# CM85F register map
Registers are read-write, no defined reset value unless marked. A register's access mark holds for its fields unless they carry their own. Offsets are from the block's base; [hi:lo] are bit positions; {n}, {i} and the like mark numbered series; 'fields as' and 'values as' point back to an identical list.

## SCB — System Control Block
Base 0xE000ECFC
0x00 REVIDR ro — Revision ID Register provides additional implementation-specific minor revision that can be interpreted with the CPUID register
  [31:0] IMPLEMENTATION_SPECIFIC — Implementation-specific minor revision information that can be interpreted with the CPUID register.
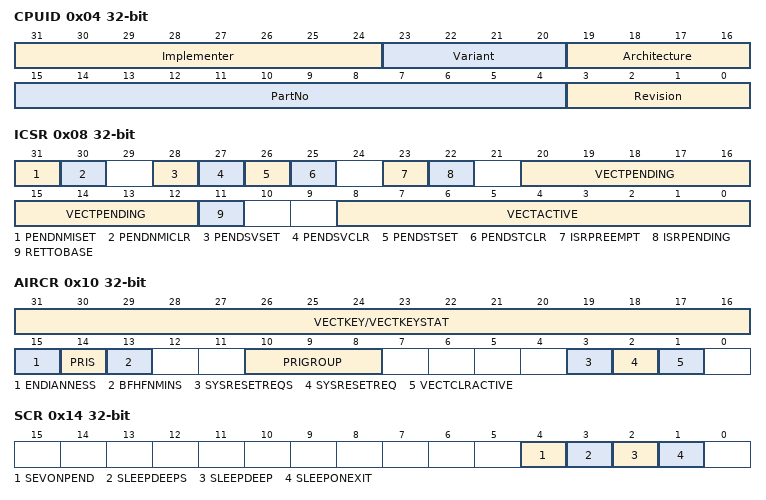
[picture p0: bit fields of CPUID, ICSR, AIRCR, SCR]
0x04 CPUID ro — CPUID Base Register contains the processor part number, version, and implementation information
  [31:24] Implementer — Implementer code
  [23:20] Variant — Variant number, the n value in the rnpm product revision identifier
  [19:16] Architecture — Reads as 0xF
    15=Armv8.1-M with Main Extension
  [15:4] PartNo — Part number of the processor
  [3:0] Revision — Revision number, the m value in the rnpm product revision identifier
0x08 ICSR — Interrupt Control and State Register provides a set-pending bit for the non-maskable interrupt exception, and set-pending and clear-pending bits for the PendSV and SysTick exceptions
  [31] PENDNMISET — On writes, makes the NMI exception pending
    0=On writes, ignored; on reads, NMI exception is not pending; 1=On writes, Changes NMI exception state to pending; on reads, NMI exception is pending
  [30] PENDNMICLR — Pend NMI clear bit (write-only)
    0=No effect; 1=Clear pending status
  [28] PENDSVSET — PendSV set-pending bit
    0=On writes, ignored; on reads, PendSV exception is not pending; 1=On writes, Changes PendSV exception state to pending; on reads, PendSV exception is pending
  [27] PENDSVCLR — PendSV clear-pending bit (write-only)
    0=No effect; 1=Clear pending status
  [26] PENDSTSET — SysTick exception set-pending bit
    0=On writes, ignored; on reads, SysTick exception is not pending; 1=On writes, Changes SysTick exception state to pending; on reads, SysTick exception is pending
  [25] PENDSTCLR — SysTick exception clear-pending bit
    0=No effect; 1=Clear pending status
  [23] ISRPREEMPT — Indicates whether a pending exception is handled on exit from debug state.
    0=Pending exception is not handled on exit from debug state; 1=Pending exception is handled on exit from debug state
  [22] ISRPENDING — Interrupt pending flag, excluding NMI and Faults
    0=Interrupt not pending; 1=Interrupt pending
  [20:12] VECTPENDING — Indicates the exception number of the highest priority pending enabled exception
  [11] RETTOBASE — Indicates whether there are pre-empted active exceptions
    0=There are pre-empted active exceptions to execute; 1=There are no active exceptions, or the currently executing exception is the only active exception
  [8:0] VECTACTIVE — Contains the active exception number
0x0C VTOR — Vector Table Offset Register indicates the offset of the vector table base address from memory address 0x00000000
  [31:7] TBLOFF — Bits[31:7] of the vector table address
0x10 AIRCR — Application Interrupt and Reset Control Register sets or returns interrupt control data
  [31:16] VECTKEY/VECTKEYSTAT — Register key. Reads as 0x0FA05, On writes, write 0x5FA to VECTKEY, otherwise the write is ignored.
  [15] ENDIANNESS — Data endianness
    0=Little endian; 1=Big endian
  [14] PRIS — Prioritize Secure exceptions
    0=Priority ranges of Secure and Non-secure exceptions are identical; 1=Non-secure exceptions are de-prioritized
  [13] BFHFNMINS — BusFault, HardFault, and NMI Non-secure enable
    0=BusFault, HardFault, and NMI are Secure; 1=BusFault and NMI are Non-secure and exceptions can target Non-secure HardFault
  [10:8] PRIGROUP — Interrupt priority grouping
  [3] SYSRESETREQS — System reset request, Secure state only
    0=SYSRESETREQ functionality is available to both Security states; 1=SYSRESETREQ functionality is only available to Secure state
  [2] SYSRESETREQ — System Reset Request
    0=Do not request a reset; 1=Request reset
  [1] VECTCLRACTIVE — Reserved for Debug use. This bit reads as 0. When writing to the register you must write 0 to this bit, otherwise behavior is UNPREDICTABLE
0x14 SCR ro — System Control Register controls features of entry to and exit from low-power state
  [4] SEVONPEND — Determines whether an interrupt assigned to the same Security state as the SEVONPEND bit transitioning from inactive state to pending state generates a wakeup event
    0=Transitions from inactive to pending are not wakeup events; 1=Transitions from inactive to pending are wakeup events
  [3] SLEEPDEEPS — Controls whether the SLEEPDEEP bit is only accessible from the Secure state
    0=The SLEEPDEEP bit accessible from both Security states; 1=The SLEEPDEEP bit behaves as RAZ/WI when accessed from the Non-secure state
  [2] SLEEPDEEP — Indicates whether the processor uses sleep or deep sleep as its low-power mode
    0=Sleep; 1=Deep sleep
  [1] SLEEPONEXIT — Indicates sleep-on-exit when returning from Handler mode to Thread mode
    0=Do not sleep when returning to Thread mode; 1=Enter sleep, or deep sleep, on return from an ISR
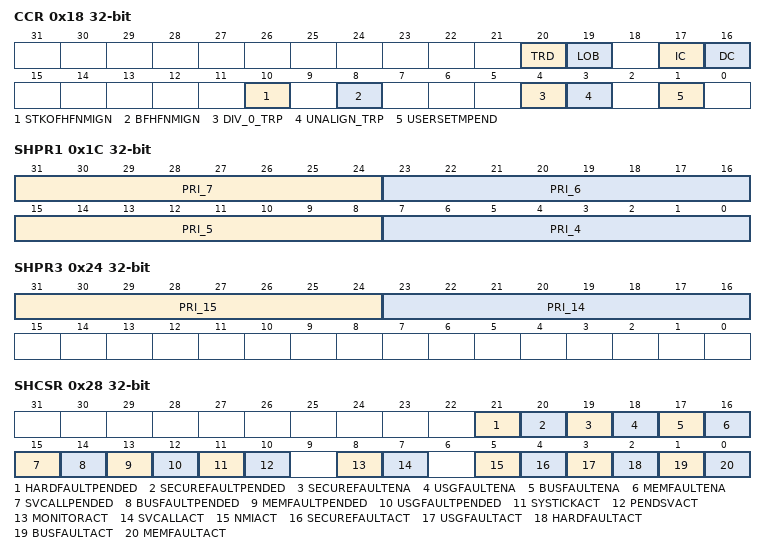
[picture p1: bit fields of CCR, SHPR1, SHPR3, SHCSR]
0x18 CCR — Configuration and Control Register indicates some aspects of the behavior of the processor
  [20] TRD — Thread reentrancy disabled
    0=Integrity signature checking not performed; 1=Integrity signature checking performed
  [19] LOB — Loop and branch info cache enable
    0=Branch cache disabled for the selected Security state; 1=Branch cache enabled for the selected Security state
  [17] IC — Instruction cache enable
    0=Instruction caches disabled for the selected Security state; 1=Instruction caches enabled for the selected Security state
  [16] DC — Data cache enable
    0=Data caching disabled; 1=Data caching enabled
  [10] STKOFHFNMIGN — Controls the effect of a stack limit violation while executing at a requested priority less than 0
    0=Stack limit faults not ignored; 1=Stack limit faults at requested priorities of less than 0 ignored
  [8] BFHFNMIGN — Determines the effect of precise bus faults on handlers running at a requested priority less than 0
    0=Precise bus faults are not ignored; 1=Precise bus faults at requested priorities of less than 0 are ignored
  [4] DIV_0_TRP — Divide by zero trap. Controls the generation of a DIVBYZERO UsageFault when attempting to perform integer division by zero.
    0=Trapping disabled; 1=Trapping enabled
  [3] UNALIGN_TRP — Controls the trapping of unaligned word or halfword accesses
    0=Trapping disabled; 1=Trapping enabled
  [1] USERSETMPEND — User set main pending. Determines whether unprivileged accesses are permitted to pend interrupts from the STIR.
    0=Unprivileged accesses to the STIR generate a fault; 1=Unprivileged accesses to the STIR are permitted
0x1C SHPR1 — System Handler Priority Register 1 sets or returns priority for system handlers 4-7
  [31:24] PRI_7 — Priority of system handler 7, SecureFault
  [23:16] PRI_6 — Priority of system handler 6, UsageFault
  [15:8] PRI_5 — Priority of system handler 5, BusFault
  [7:0] PRI_4 — Priority of system handler 4, MemManage
0x20 SHPR2 — System Handler Priority Register 2 sets or returns priority for system handler 8-11
  [31:24] PRI_11 — Priority of system handler 11, SVCall
0x24 SHPR3 — System Handler Priority Register 3 sets or returns priority for system handlers 12-15
  [31:24] PRI_15 — Priority of system handler 15, SysTick
  [23:16] PRI_14 — Priority of system handler 14, PendSV
0x28 SHCSR — System Handler Control and State Register enables the system handlers and indicates the pending status of the BusFault, MemManage fault, and SVC exceptions, and indicates the active status of the system handlers
  [21] HARDFAULTPENDED — HardFault exception pended state bit, set to 1 to allow exception modification
  [20] SECUREFAULTPENDED — SecureFault exception pended state bit, set to 1 to allow exception modification
  [19] SECUREFAULTENA — RES0
  [18] USGFAULTENA — UsageFault enable
    0=Disable the exception; 1=Enable the exception
  [17] BUSFAULTENA — BusFault enable
    0=Disable the exception; 1=Enable the exception
  [16] MEMFAULTENA — MemManage enable
    0=Disable the exception; 1=Enable the exception
  [15] SVCALLPENDED — SVCall pending
    0=SVCall execption is not pending; 1=SVCall execption is pending
  [14] BUSFAULTPENDED — BusFault pending
    values as SVCALLPENDED
  [13] MEMFAULTPENDED — MemManage exception pending
    values as SVCALLPENDED
  [12] USGFAULTPENDED — UsageFault exception pending
    values as SVCALLPENDED
  [11] SYSTICKACT — SysTick exception active
    0=SVCall execption is not active; 1=SVCall execption is active
  [10] PENDSVACT — PendSV exception active
    0=PendSV exception is not active; 1=PendSV exception is active
  [8] MONITORACT — Debug monitor active
    0=DebugMonitor not active; 1=DebugMonitor is active
  [7] SVCALLACT — SVCall active
    0=SVCall is not active; 1=SVCall is active
  [5] NMIACT — NMI exception active
    0=NMI exception is not active; 1=NMI exception is active
  [4] SECUREFAULTACT — SecureFault exception active state
    0=SecureFault exception is not active; 1=SecureFault exception is active
  [3] USGFAULTACT — UsageFault exception active
    0=UsageFault exception is not active; 1=UsageFault exception is active
  [2] HARDFAULTACT — HardFault exception active
    0=HardFault exception is not active; 1=HardFault exception is active
  [1] BUSFAULTACT — BusFault exception active
    0=BusFault exception is not active; 1=BusFault exception is active
  [0] MEMFAULTACT — MemManage exception active
    0=MemManage exception is not active; 1=MemManage exception is active
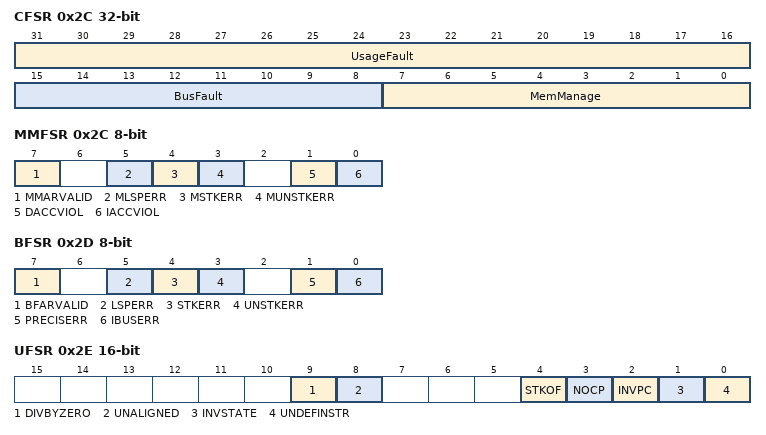
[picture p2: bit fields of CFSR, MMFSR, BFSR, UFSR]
0x2C CFSR — Configurable Fault Status Register indicates the cause of a MemManage fault, BusFault, or UsageFault
  [31:16] UsageFault — Provides information on UsageFault exceptions
  [15:8] BusFault — Provides information on BusFault exceptions
  [7:0] MemManage — Provides information on MemManage exceptions
0x2C MMFSR 8-bit — MemManage Fault Status Register indicates the cause of memory access faults
  [7] MMARVALID — MemManage Fault Address Register (MMFAR) valid flag
    0=MMFAR content not valid; 1=MMFAR content valid
  [5] MLSPERR — MemManage lazy state preservation error flag
    0=No MemManage fault occurred during floating-point lazy state preservation; 1=A MemManage fault occurred during floating-point lazy state preservation
  [4] MSTKERR — MemManage fault on stacking for exception entry
    0=No stacking fault; 1=Stacking for an exception entry has caused one or more access violations
  [3] MUNSTKERR — MemManage fault on unstacking for a return from exception
    0=No unstacking fault; 1=Unstack for an exception return has caused one or more access violations
  [1] DACCVIOL — Data access violation flag
    0=No data access violation fault; 1=data access violation fault occurred
  [0] IACCVIOL — Instruction access violation flag
    0=No instruction access violation fault; 1=Instruction acce ss violation fault occurred
0x2D BFSR 8-bit — Bus Fault Status Register indicate the cause of a bus access fault
  [7] BFARVALID — BusFault Address Register (BFAR) valid flag.
    0=BFAR content not valid; 1=BFAR content valid
  [5] LSPERR — Lazy state preservation error
    0=No BusFault occurred during FP lazy state preservation; 1=BusFault occurred during FP lazy state preservation
  [4] STKERR — BusFault on stacking for exception entry
    0=No stacking fault; 1=Stacking for an exception entry has caused one or more BusFaults
  [3] UNSTKERR — BusFault on unstacking for a return from exception
    0=No unstacking fault; 1=Unstack for an exception return has caused one or more BusFaults
  [1] PRECISERR — Precise data bus error
    0=No precise data bus error; 1=Precise data bus error occurred
  [0] IBUSERR — Instruction bus error
    0=No instruction bus error; 1=Instruction bus error has occurred
0x2E UFSR 16-bit — Usage Fault Status Register indicates the cause of a UsageFault
  [all] fields
    0=Error has not occurred; 1=Error has occurred
  [9] DIVBYZERO — Divide by zero flag. Sticky flag indicating whether an integer division by zero error has occurred.
  [8] UNALIGNED — Unaligned access flag. Sticky flag indicating whether an unaligned access error has occurred.
  [4] STKOF — Stack overflow flag. Sticky flag indicating whether a stack overflow error has occurred.
  [3] NOCP — No coprocessor flag. Sticky flag indicating whether a coprocessor disabled or not present error has occurred.
  [2] INVPC — Invalid PC flag. Sticky flag indicating whether an integrity check error has occurred.
  [1] INVSTATE — Invalid state flag. Sticky flag indicating whether an EPSR.T or EPSR.IT validity error has occurred.
  [0] UNDEFINSTR — Undefined instruction flag. Sticky flag indicating whether an undefined instruction error has occurred.
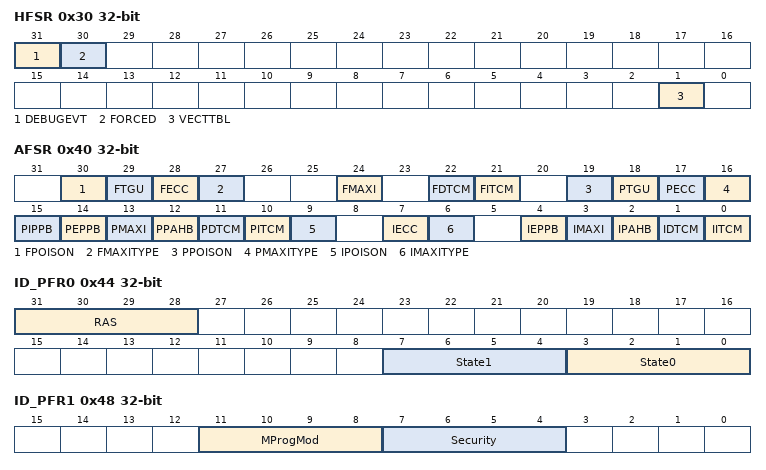
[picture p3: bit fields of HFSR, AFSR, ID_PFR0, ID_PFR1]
0x30 HFSR — HardFault Status Register gives information about events that activate the HardFault handler
  [31] DEBUGEVT — Reserved for Debug use. When writing to the register you must write 1 to this bit, otherwise behavior is unpredictable.
  [30] FORCED — Indicates a forced HardFault, generated by escalation of a fault with configurable priority that cannot be handled, either because of priority or because it is disabled
    0=No forced HardFault; 1=Forced HardFault
  [1] VECTTBL — Indicates a HardFault on a vector table read during exception processing
    0=No HardFault on vector table read; 1=HardFault on vector table read
0x38 MMFAR — MemManage Fault Address Register shows the address of the memory location that caused a Memory Protection Unit (MPU) fault
0x3C BFAR — BusFault Address Register shows the address associated with a precise data access BusFault
0x40 AFSR ro — Auxiliary Fault Status Register provides fault status information
  [30] FPOISON — Fetch fault caused by RPOISON or TEBRx.POISON
  [29] FTGU — Fetch fault caused by TCM Gate Unit (TGU) security violation
  [28] FECC — Fetch fault caused by uncorrectable Error Correcting Code (ECC) error
  [27] FMAXITYPE — AXI response that caused the fetch fault. Only valid when AFSR.FMAXI is 1.
    0=SLVERR
  [24] FMAXI — Fetch fault on Master AXI (M-AXI) interface
  [22] FDTCM — Fetch fault on Data Tightly Coupled Memory (DTCM) interface
  [21] FITCM — Fetch fault on Instruction Tightly Coupled Memory (ITCM) interface
  [19] PPOISON — Precise fault caused by RPOISON or TEBRx.POISON
  [18] PTGU — Precise fault caused by TGU security violation
  [17] PECC — Precise fault caused by uncorrectable ECC error
  [16] PMAXITYPE — AXI response that caused the precise fault. Only valid when AFSR.PMAXI is 1.
    0=SLVERR
  [15] PIPPB — Precise fault on Internal Private Peripheral Bus (EPPB) interface
  [14] PEPPB — Precise fault on External Private Peripheral Bus (EPPB) interface
  [13] PMAXI — Precise fault on M-AXI interface
  [12] PPAHB — Precise fault on Peripheral AHB (P-AHB) interface
  [11] PDTCM — Precise fault on DTCM interface
  [10] PITCM — Precise fault on ITCM interface
  [9] IPOISON — Imprecise BusFault because of RPOISON
  [7] IECC — Imprecise fault caused by uncorrectable ECC error
  [6] IMAXITYPE — AXI response that caused the imprecise fault. Only valid when AFSR.IMAXI is 1.
    0=SLVERR
  [4] IEPPB — Imprecise fault on EPPB interface
  [3] IMAXI — Imprecise fault on M-AXI interface
  [2] IPAHB — Imprecise fault on P-AHB interface
  [1] IDTCM — Imprecise fault on DTCM interface
  [0] IITCM — Imprecise fault on ITCM interface
0x44 ID_PFR0 ro — Processor Feature Register 0 indicates the version of the Reliability, Availability, and Serviceability (RAS) extension supported
  [31:28] RAS — Identifies which version of the RAS architecture is implemented
    2=Version 1
  [7:4] State1 — T32 instruction set support
    3=T32 instruction set including Thumb-2 technology is implemented
  [3:0] State0 — A32 instruction set support
    0=A32 instruction set is not implemented
0x48 ID_PFR1 ro — Processor Feature Register 1 gives information about the programmers' model and Extensions support
  [11:8] MProgMod — M-profile programmers' model
    2=Two-stack programmers' model
  [7:4] Security — Identifies whether the Security Extension in implemented
    0=Security Extension is not implemented; 3=Security Extension implemented with state handling instructions
0x4C ID_DFR0 ro — Debug Feature Register 0 no information available
  [28:21] UDE — Indicates support for the Unprivileged Debug Extension
    0=Unprivileged Debug Extension is not implemented; 1=Unprivileged Debug Extension is implemented
  [23:20] MProfDbg — Indicates the supported M-Proﬁle debug architecture
    0=Halting debug is not implemented; 2=Halting debug is implemented
0x50 ID_AFR0 ro — Auxiliary Feature Register 0 the ID_AFR0 is fully Reserved, RES0
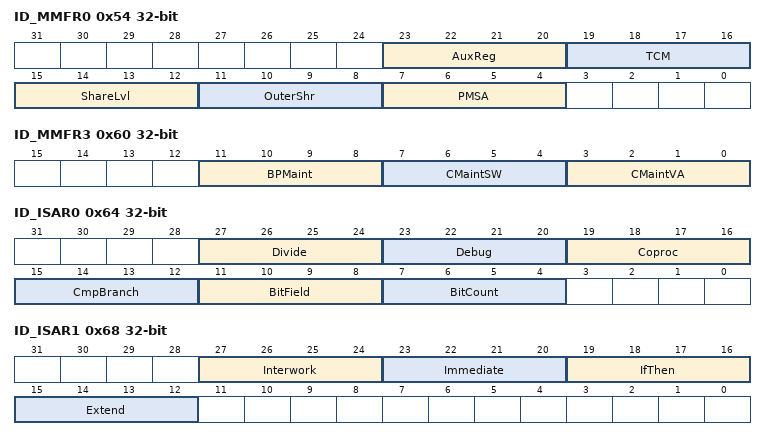
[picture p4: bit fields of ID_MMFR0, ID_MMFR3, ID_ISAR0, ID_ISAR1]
0x54 ID_MMFR0 ro — Memory Model Feature Register 0 gives information about the implemented memory model and memory management support
  [23:20] AuxReg — Indicates support for Auxiliary Control registers
    1=Auxiliary Control registers are supported
  [19:16] TCM — Indicates support for TCMs
    1=TCMs are supported
  [15:12] ShareLvl — Indicates the number of Shareability levels implemented
    1=Two levels of Shareability implemented
  [11:8] OuterShr — Indicates the outermost Shareability domain implemented
    0=Implemented as Non-cacheable
  [7:4] PMSA — Indicates support for the protected memory system architecture (PMSA)
    4=Supports PMSAv8
0x58 ID_MMFR1 ro — Memory Model Feature Register 1 gives information about the IMPLEMENTATION DEFINED memory model and memory management support. This register is Reserved, RES0.
0x5C ID_MMFR2 ro — Memory Model Feature Register 2 gives information about the implemented memory model and memory management support
  [27:24] WFIStall — Indicates the support for Wait For Interrupt (WFI) stalling
    1=WFI has the ability to stall
0x60 ID_MMFR3 ro — Memory Model Feature Register 3 gives information about the implemented memory model and memory management support
  [11:8] BPMaint — Indicates the supported branch predictor maintenance
    0=Branch predictor maintenance is not supported
  [7:4] CMaintSW — Indicates the supported cache maintenance operations by set/way
    1=Cache maintenance operations by set/way are supported
  [3:0] CMaintVA — Indicates the supported cache maintenance operations by address
    1=Cache maintenance operations by address are supported
0x64 ID_ISAR0 ro — Instruction Set Attribute Register 0 gives information about the implemented instruction set
  [27:24] Divide — Indicates the supported divide instructions
    1=Supports SDIV and UDIV instructions
  [23:20] Debug — Indicates the implemented debug instructions
    1=Supports BKPT instruction
  [19:16] Coproc — Indicates the supported coprocessor instructions
    0=Coprocessor instructions are not supported, except for, floating-point or MVE; 4=Coprocessor instructions are supported
  [15:12] CmpBranch — Indicates the supported combined Compare and Branch instructions
    3=Supports CBNZ and CBZ instructions along with non-predicated low-overhead looping and branch future instructions. Branch future instructions behave as NOPs
  [11:8] BitField — Indicates the supported bit field instructions
    1=BFC, BFI, SBFX, and UBFX are supported
  [7:4] BitCount — Indicates the supported bit count instructions
    1=CLZ supported
0x68 ID_ISAR1 ro — Instruction Set Attribute Register 1 gives information about the implemented instruction set
  [27:24] Interwork — Indicates the implemented interworking instructions
    2=BLX, BX, and loads to PC network
  [23:20] Immediate — Indicates the implemented data-processing instructions with long immediates
    2=ADDW, MOVW, MOVT, and SUBW are supported
  [19:16] IfThen — Indicates the implemented If-Then instructions
    1=IT instruction supported
  [15:12] Extend — Indicates the implemented Extend instructions
    2=Adds SXTB16, SXTAB, SXTAB16, SXTAH, UXTB16, UXTAB, UXTAB16, and UXTAH DSP Extension only
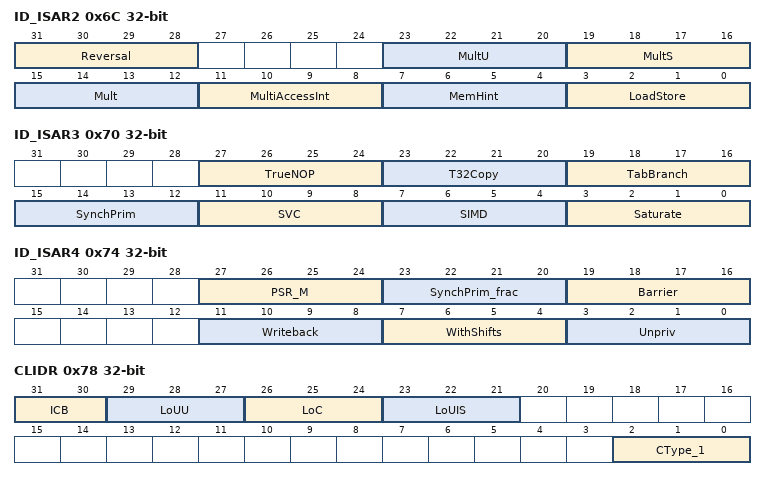
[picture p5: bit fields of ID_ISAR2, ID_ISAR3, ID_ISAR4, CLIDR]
0x6C ID_ISAR2 ro — Instruction Set Attribute Register 2 gives information about the implemented instruction set
  [31:28] Reversal — Indicates the implemented reversal instructions
    2=REV, REV16, REVSH, and RBIT instructions are supported
  [23:20] MultU — Indicates the implemented Advanced Unsigned Multiple instructions
    2=Adds UMAAL, DSP Extension only
  [19:16] MultS — Indicates the implemented Advanced Signed Multiple instructions
    3=Adds all saturating and DSP signed multiplies, DSP Extension only
  [15:12] Mult — Indicates the implemented additional Multiply instructions
    2=MUL, MLA, and MLS instructions
  [11:8] MultiAccessInt — Multi-access instructions. Indicates the support for interruptible multi-access instructions
    2=LDM, STM, and CLRM instructions are continuable
  [7:4] MemHint — Memory hint. Indicates the implemented memory hint instructions
    3=PLI and PLD instructions implemented
  [3:0] LoadStore — Indicates the implemented additional load/store instructions
    2=Supports load-acquire, store-release, and exclusive load and store instructions
0x70 ID_ISAR3 ro — Instruction Set Attribute Register 3 gives information about the implemented instruction set
  [27:24] TrueNOP — Indicates the implemented true NOP instructions
    1=NOP instruction and compatible hints are implemented
  [23:20] T32Copy — Indicates the support for T32 non-flag setting MOV instructions
    1=Encoding T1 of MOV (register) supports copying a low register to a low register
  [19:16] TabBranch — Indicates the implemented table branch instructions
    1=TBB and TBH are implemented
  [15:12] SynchPrim — Used with ID_ISAR4.SynchPrim_frac to indicate the implemented synchronization primitive instructions
    1=LDREX, STREX, LDREXB, STREXB, LDREXH, STREXH, and CLREX are implemented
  [11:8] SVC — Indicates the implemented SVC instructions
    1=SVC instruction implemented
  [7:4] SIMD — Indicates the implemented SIMD instructions
    3=SSAT, USAT, Q-bit, packed arithmetic, and GE-bits are implemented
  [3:0] Saturate — Indicates the implemented saturating instructions
    1=QADD, QDADD, QDSUB, QSUB, and Q-bit implemented, DSP Extension only
0x74 ID_ISAR4 ro — Instruction Set Attribute Register 4 gives information about the implemented instruction set
  [27:24] PSR_M — Indicates the implemented M-profile instructions to modify the PSRs
    1=M-profile forms of CPS, MRS, and MSR instructions are implemented
  [23:20] SynchPrim_frac — Used in conjunction with ID_ISAR3.SynchPrim to indicate the implemented synchronization primitive instructions
    1=LDREX, STREX, CLREX, LDREXB, LDREXH, STREXB, and STREXH instructions are implemented
  [19:16] Barrier — Indicates the implemented Barrier instructions
    1=CSDB, DMB, DSB, ISB, PSSBB, and SSBB barrier instructions implemented
  [11:8] Writeback — Indicates the support for writeback addressing modes
    1=All writeback addressing modes supported
  [7:4] WithShifts — Indicates the support for writeback addressing modes
    3=Support for constant shifts on load/store and other instructions
  [3:0] Unpriv — Indicates the implemented unprivileged instructions
    2=LDRBT, LDRHT, LDRSBT, LDRSHT, LDRT, STRBT, STRHT, and STRT implemented
0x78 ID_ISAR5 ro — Instruction Set Attribute Register 5 gives information about the implemented instruction set. This register is Reserved, RES0
0x78 CLIDR ro — Cache Level ID Register the CLIDR identifies the type of caches implemented and the level of coherency and unification
  [31:30] ICB — Inner cache boundary. The Cortex-M55 processor supports inner cacheability on the bus. Therefore, this field cannot disclose any information.
  [29:27] LoUU — Level of Unification Uniprocessor
    0=No cache; 1=L1 data cache or instruction cache is implemented
  [26:24] LoC — Level of Coherency
    values as LoUU
  [23:21] LoUIS — Level of Unification Inner Shareable
    values as LoUU
  [2:0] CType_1 — L1 cache type
    0=No cache; 1=Instruction cache only; 2=Data cache only; 3=instruction and data caches
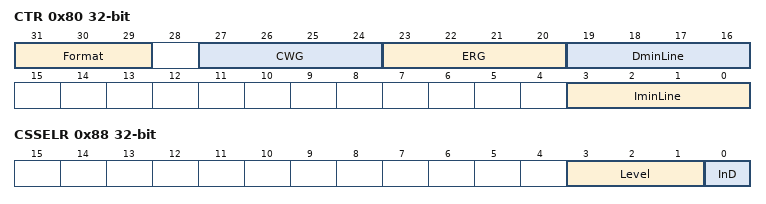
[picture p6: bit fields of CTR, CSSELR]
0x80 CTR ro — Cache Type Register the CTR provides information about the architecture of the caches
  [31:29] Format — Cache type register format
    4=Cache type information is provided
  [27:24] CWG — Cache Write-Back Granule
  [23:20] ERG — Exclusives Reservation Granule
  [19:16] DminLine — Data cache minimum line length. Log2 of the number of words in the smallest cache line of all the data caches and unified caches that are controlled by the processor.
  [3:0] IminLine — Instruction cache minimum line length. Log2 of the number of words in the smallest cache line of all the instruction caches that are controlled by the processor.
0x84 CCSIDR ro — Current Cache Size ID Register provides information about the architecture of the Level 1 (L1) instruction or data cache that the CSSELR selects.
  [30] WB — Indicates support available for Write-Back
    0=Not available; 1=Available
  [29] RA — Indicates support available for read allocation
    0=Not available; 1=Available
  [28] WA — Indicates support available for write allocation
    0=Not available; 1=Available
  [27:13] NumSet — Indicates the number of sets
  [12:3] Associativity — Indicates associativity
  [?] WT — Indicates support available for Write-Through
    0=Not available; 1=Available
  [2:0] LineSize — Indicates the number of words in each cache line
    0=16 bytes; 1=32 bytes
0x88 CSSELR — Cache Size Selection Register the CSSELR selects the current CCSIDR by specifying the cache level and the type of cache
  [3:1] Level — Cache level of required cache
    0=L1 cache
  [0] InD — Instruction not data bit
    0=L1 data cache; 1=L1 instruction cache
0x8C CPACR — Coprocessor Access Control Register specifies the access privileges for coprocessors
  [23:22] CP_11 — CP11 Privilege. The value in this field is ignored.
  [21:20] CP_10 — CP10 Privilege. Defines the access rights for the floating-point functionality.
    0=All accesses to the FP Extension result in NOCP UsageFault; 1=Unprivileged accesses to the FP Extension result in NOCP UsageFault; 3=Full access to the FP Extension
  [n+1:n] CP[{n}] (n=0..7) — Coprocessor {n} privilege
    0=Access denied. Any attempted access generates a NOCP UsageFault; 1=Privileged access only. An unprivileged access generates a NOCP UsageFault; 3=Full access
0x90 NSACR — Non-secure Access Control Register in an implementation with the Security Extension, the NSACR register defines the Non-secure access permissions for both the Floating-point and MVE and coprocessors CP m, bit[ m], for m = 0-7. If MVE is implemented, this register specifies the Non-secure permissions for MVE
  [10] CP_10 — Enables non-secure access to the Floating-point and MVE
    0=Non-secure accesses to the Floating-point Extension generate a NOCP UsageFault; 1=Non-secure access to the Floating-point and MVE permitted
  [11:1] CP_11 — Enables non-secure access to the Floating-point and MVE. Programming with a different value other than that used for CP10 is unpredictable.
  [n] CP[{n}] (n=0..7) — Enables Non-secure access to this coprocessor
    0=Non-secure accesses to this coprocessor generate a NOCP UsageFault; 1=Non-secure access to this coprocessor permitted
